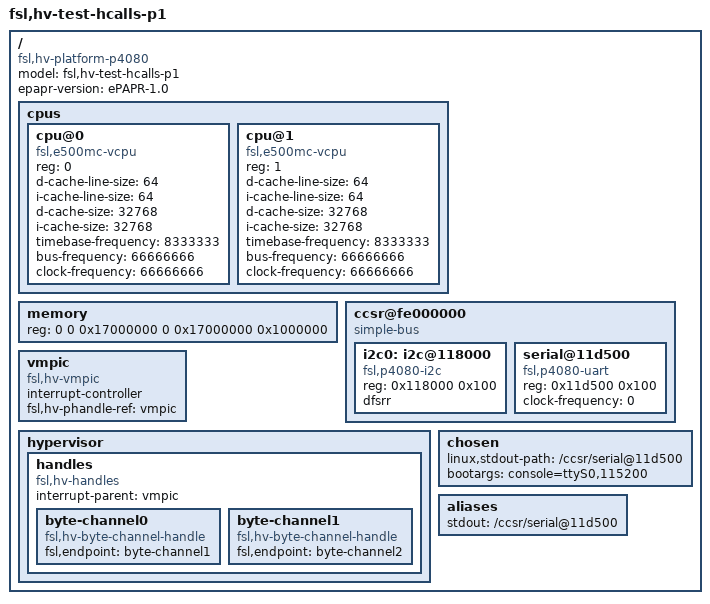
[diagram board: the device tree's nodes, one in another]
/dts-v1/;

/ {
	compatible = "fsl,hv-platform-p4080", "fsl,hv-platform";
	model = "fsl,hv-test-hcalls-p1";
	epapr-version = "ePAPR-1.0";
	#address-cells = <2>;
	#size-cells = <1>;

	cpus {
		#address-cells = <1>;
		#size-cells = <0>;

		cpu@0 {
			device_type = "cpu";
			compatible = "fsl,e500mc-vcpu";
			reg = <0>;
			d-cache-line-size = <64>;
			i-cache-line-size = <64>;
			d-cache-size = <32768>;
			i-cache-size = <32768>;
			timebase-frequency = <8333333>;
			bus-frequency = <66666666>;
			clock-frequency = <66666666>;
		};

		cpu@1 {
			device_type = "cpu";
			compatible = "fsl,e500mc-vcpu";
			reg = <1>;
			d-cache-line-size = <64>;
			i-cache-line-size = <64>;
			d-cache-size = <32768>;
			i-cache-size = <32768>;
			timebase-frequency = <8333333>;
			bus-frequency = <66666666>;
			clock-frequency = <66666666>;
		};
	};
	
	memory {
		reg = <0 0 0x17000000 0 0x17000000 0x1000000>;
		device_type = "memory";
	};
	
	ccsr@fe000000 {
		#address-cells = <1>;
		#size-cells = <1>;
		compatible = "simple-bus";
		device_type = "soc";
		ranges = <0 0 0xfe000000 0x400000>;

		i2c0: i2c@118000 {
			device_type = "i2c";
			compatible = "fsl,p4080-i2c",
			             "fsl,i2c", "fsl-i2c";
			reg = <0x118000 0x100>;
//			interrupts = <38 2>;
//			interrupt-parent = <&mpic>;
			dfsrr;
		};

		serial@11d500 {
			device_type = "serial";
			compatible = "fsl,p4080-uart",
			             "fsl,ns16550", "ns16550";
			reg = <0x11d500 0x100>;
			clock-frequency = <0>;
//			interrupts = <37 2>;
//			interrupt-parent = <&mpic>;
		};
	};

	vmpic:vmpic {
		compatible = "fsl,hv-vmpic";
		interrupt-controller;
		#interrupt-cells = <2>;
		fsl,hv-phandle-ref = <&vmpic>;
	};

	hypervisor {
		handles {
			#address-cells = <1>;
			#size-cells = <0>;
			compatible = "fsl,hv-handles";
			interrupt-parent = <&vmpic>;
			
			byte-channel0 {
				compatible = "fsl,hv-byte-channel-handle";
				fsl,endpoint = "byte-channel1";
			};
	
			byte-channel1 {
				compatible = "fsl,hv-byte-channel-handle";
				fsl,endpoint = "byte-channel2";
			};
		};
	};

	chosen {
		linux,stdout-path = "/ccsr/serial@11d500";
		bootargs = "console=ttyS0,115200";
	};

	aliases {
		stdout = "/ccsr/serial@11d500";
	};
};
